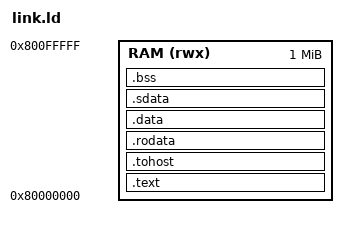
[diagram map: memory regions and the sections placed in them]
/* Single RAM region shared by the RTL testbench (tb_memory) and Spike (-m). */
OUTPUT_ARCH("riscv")
ENTRY(_start)

MEMORY
{
    RAM (rwx) : ORIGIN = 0x80000000, LENGTH = 1M
}

SECTIONS
{
    .text : {
        *(.text.init)
        *(.text .text.*)
    } > RAM

    .tohost : ALIGN(64) {
        *(.tohost)
    } > RAM

    .rodata : ALIGN(4) {
        *(.rodata .rodata.*)
        *(.srodata .srodata.*)
    } > RAM

    .data : ALIGN(4) {
        *(.data .data.*)
    } > RAM

    .sdata : ALIGN(4) {
        __global_pointer$ = . + 0x800;
        *(.sdata .sdata.*)
    } > RAM

    .bss (NOLOAD) : ALIGN(4) {
        __bss_start = .;
        *(.sbss .sbss.*)
        *(.bss .bss.*)
        *(COMMON)
        . = ALIGN(4);
        __bss_end = .;
    } > RAM

    _stack_top = ORIGIN(RAM) + LENGTH(RAM);
}
